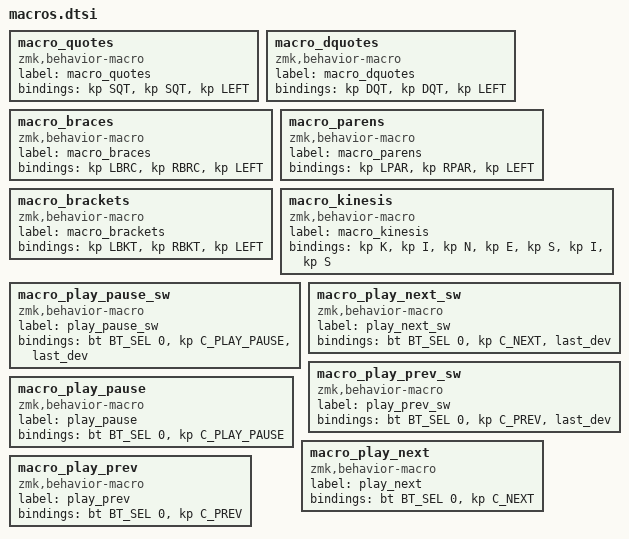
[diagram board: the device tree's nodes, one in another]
  macro_quotes: macro_quotes {
    compatible = "zmk,behavior-macro";
    label = "macro_quotes";
    #binding-cells = <0>;
    bindings = <&kp SQT>, <&kp SQT>, <&kp LEFT>;
  };
  macro_dquotes: macro_dquotes {
    compatible = "zmk,behavior-macro";
    label = "macro_dquotes";
    #binding-cells = <0>;
    bindings = <&kp DQT>, <&kp DQT>, <&kp LEFT>;
  };
  macro_braces: macro_braces {
    compatible = "zmk,behavior-macro";
    label = "macro_braces";
    #binding-cells = <0>;
    bindings = <&kp LBRC>, <&kp RBRC>, <&kp LEFT>;
  };
  macro_parens: macro_parens {
    compatible = "zmk,behavior-macro";
    label = "macro_parens";
    #binding-cells = <0>;
    bindings = <&kp LPAR>, <&kp RPAR>, <&kp LEFT>;
  };
  macro_brackets: macro_brackets {
    compatible = "zmk,behavior-macro";
    label = "macro_brackets";
    #binding-cells = <0>;
    bindings = <&kp LBKT>, <&kp RBKT>, <&kp LEFT>;
  };
  macro_kinesis: macro_kinesis {
    compatible = "zmk,behavior-macro";
    label = "macro_kinesis";
    #binding-cells = <0>;
    bindings = <&kp K>, <&kp I>, <&kp N>, <&kp E>, <&kp S>, <&kp I>, <&kp S>;
  };
  macro_play_pause_sw: macro_play_pause_sw {
    compatible = "zmk,behavior-macro";
    label = "play_pause_sw";
    #binding-cells = <0>;
    bindings
      = <&bt BT_SEL 0>
      , <&kp C_PLAY_PAUSE>
      , <&last_dev>
      ;    
  };
   macro_play_next_sw: macro_play_next_sw {
    compatible = "zmk,behavior-macro";
    label = "play_next_sw";
    #binding-cells = <0>;
    bindings
      = <&bt BT_SEL 0>
      , <&kp C_NEXT>
      , <&last_dev>
      ;    
  };

   macro_play_prev_sw: macro_play_prev_sw {
    compatible = "zmk,behavior-macro";
    label = "play_prev_sw";
    #binding-cells = <0>;
    bindings
      = <&bt BT_SEL 0>
      , <&kp C_PREV>
      , <&last_dev>
      ;    
  };

  macro_play_pause: macro_play_pause {
    compatible = "zmk,behavior-macro";
    label = "play_pause";
    #binding-cells = <0>;
    bindings
      = <&bt BT_SEL 0>
      , <&kp C_PLAY_PAUSE>
      ;    
  };
   macro_play_next: macro_play_next {
    compatible = "zmk,behavior-macro";
    label = "play_next";
    #binding-cells = <0>;
    bindings
      = <&bt BT_SEL 0>
      , <&kp C_NEXT>
      ;    
  };

   macro_play_prev: macro_play_prev {
    compatible = "zmk,behavior-macro";
    label = "play_prev";
    #binding-cells = <0>;
    bindings
      = <&bt BT_SEL 0>
      , <&kp C_PREV>
      ;    
  };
